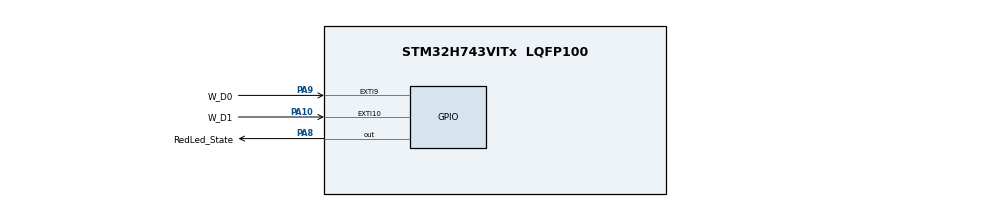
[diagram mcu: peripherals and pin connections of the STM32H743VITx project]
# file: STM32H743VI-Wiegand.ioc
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Mcu.Family=STM32H7
Mcu.Name=STM32H743VITx
Mcu.Package=LQFP100
NVIC.EXTI15_10_IRQn=true\:0\:0\:false\:false\:true\:true\:true
NVIC.EXTI9_5_IRQn=true\:0\:0\:false\:false\:true\:true\:true
NVIC.PriorityGroup=NVIC_PRIORITYGROUP_4
PA10.GPIO_Label=W_D1
PA10.GPIO_ModeDefaultEXTI=GPIO_MODE_IT_FALLING
PA10.GPIO_PuPd=GPIO_PULLUP
PA10.Signal=GPXTI10
PA8.GPIO_Label=RedLed_State
PA8.Signal=GPIO_Output
PA9.GPIO_Label=W_D0
PA9.GPIO_ModeDefaultEXTI=GPIO_MODE_IT_FALLING
PA9.GPIO_PuPd=GPIO_PULLUP
PA9.Signal=GPXTI9
ProjectManager.HeapSize=0x200
ProjectManager.StackSize=0x400
ProjectManager.TargetToolchain=STM32CubeIDE
RCC.ADCFreq_Value=129000000
RCC.APB1Freq_Value=64000000
RCC.APB2Freq_Value=64000000
RCC.APB3Freq_Value=64000000
RCC.APB4Freq_Value=64000000
RCC.CortexFreq_Value=64000000
RCC.HCLKFreq_Value=64000000
RCC.SYSCLKFreq_VALUE=64000000
RCC.USBFreq_Value=129000000
board=custom

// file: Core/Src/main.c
/* USER CODE BEGIN Header */
/**
 ******************************************************************************
 * @file           : main.c
 * @brief          : Main program body
 ******************************************************************************
 * @attention
 *
 * <h2><center>&copy; Copyright (c) 2021 STMicroelectronics.
 * All rights reserved.</center></h2>
 *
 * This software component is licensed by ST under BSD 3-Clause license,
 * the "License"; You may not use this file except in compliance with the
 * License. You may obtain a copy of the License at:
 *                        opensource.org/licenses/BSD-3-Clause
 *
 ******************************************************************************
 */
/* USER CODE END Header */
#include <ib_rfid.h>
#include "main.h"

void SystemClock_Config(void);
static void MX_GPIO_Init(void);

/* USER CODE BEGIN 0 */
void New_RFID(uint32_t code) {
	uint32_t card_rfid = code;
	HAL_GPIO_TogglePin(RedLed_State_GPIO_Port, RedLed_State_Pin);
}
/* USER CODE END 0 */

int main(void) {

	/* MCU Configuration--------------------------------------------------------*/

	/* Reset of all peripherals, Initializes the Flash interface and the Systick. */
	HAL_Init();

	/* Configure the system clock */
	SystemClock_Config();

	/* Initialize all configured peripherals */
	MX_GPIO_Init();
	/* USER CODE BEGIN 2 */
	HAL_GPIO_WritePin(RedLed_State_GPIO_Port, RedLed_State_Pin, GPIO_PIN_SET);
	rfid_init(W_D0_Pin, W_D1_Pin, 100, New_RFID);
	/* USER CODE END 2 */

	/* Infinite loop */
	/* USER CODE BEGIN WHILE */
	while (1) {
		rfid_loop();
		/* USER CODE END WHILE */

	}
}

void SystemClock_Config(void) {
	RCC_OscInitTypeDef RCC_OscInitStruct = { 0 };
	RCC_ClkInitTypeDef RCC_ClkInitStruct = { 0 };

	/** Supply configuration update enable
	 */
	HAL_PWREx_ConfigSupply(PWR_LDO_SUPPLY);
	/** Configure the main internal regulator output voltage
	 */
	__HAL_PWR_VOLTAGESCALING_CONFIG(PWR_REGULATOR_VOLTAGE_SCALE3);

	while (!__HAL_PWR_GET_FLAG(PWR_FLAG_VOSRDY)) {
	}
	/** Initializes the RCC Oscillators according to the specified parameters
	 * in the RCC_OscInitTypeDef structure.
	 */
	RCC_OscInitStruct.OscillatorType = RCC_OSCILLATORTYPE_HSI;
	RCC_OscInitStruct.HSIState = RCC_HSI_DIV1;
	RCC_OscInitStruct.HSICalibrationValue = RCC_HSICALIBRATION_DEFAULT;
	RCC_OscInitStruct.PLL.PLLState = RCC_PLL_NONE;
	if (HAL_RCC_OscConfig(&RCC_OscInitStruct) != HAL_OK) {
		Error_Handler();
	}
	/** Initializes the CPU, AHB and APB buses clocks
	 */
	RCC_ClkInitStruct.ClockType = RCC_CLOCKTYPE_HCLK | RCC_CLOCKTYPE_SYSCLK
			| RCC_CLOCKTYPE_PCLK1 | RCC_CLOCKTYPE_PCLK2 | RCC_CLOCKTYPE_D3PCLK1
			| RCC_CLOCKTYPE_D1PCLK1;
	RCC_ClkInitStruct.SYSCLKSource = RCC_SYSCLKSOURCE_HSI;
	RCC_ClkInitStruct.SYSCLKDivider = RCC_SYSCLK_DIV1;
	RCC_ClkInitStruct.AHBCLKDivider = RCC_HCLK_DIV1;
	RCC_ClkInitStruct.APB3CLKDivider = RCC_APB3_DIV1;
	RCC_ClkInitStruct.APB1CLKDivider = RCC_APB1_DIV1;
	RCC_ClkInitStruct.APB2CLKDivider = RCC_APB2_DIV1;
	RCC_ClkInitStruct.APB4CLKDivider = RCC_APB4_DIV1;

	if (HAL_RCC_ClockConfig(&RCC_ClkInitStruct, FLASH_LATENCY_1) != HAL_OK) {
		Error_Handler();
	}
}

static void MX_GPIO_Init(void) {
	GPIO_InitTypeDef GPIO_InitStruct = { 0 };

	/* GPIO Ports Clock Enable */
	__HAL_RCC_GPIOA_CLK_ENABLE();

	/*Configure GPIO pin Output Level */
	HAL_GPIO_WritePin(RedLed_State_GPIO_Port, RedLed_State_Pin, GPIO_PIN_RESET);

	/*Configure GPIO pin : RedLed_State_Pin */
	GPIO_InitStruct.Pin = RedLed_State_Pin;
	GPIO_InitStruct.Mode = GPIO_MODE_OUTPUT_PP;
	GPIO_InitStruct.Pull = GPIO_NOPULL;
	GPIO_InitStruct.Speed = GPIO_SPEED_FREQ_LOW;
	HAL_GPIO_Init(RedLed_State_GPIO_Port, &GPIO_InitStruct);

	/*Configure GPIO pins : W_D0_Pin W_D1_Pin */
	GPIO_InitStruct.Pin = W_D0_Pin | W_D1_Pin;
	GPIO_InitStruct.Mode = GPIO_MODE_IT_FALLING;
	GPIO_InitStruct.Pull = GPIO_PULLUP;
	HAL_GPIO_Init(GPIOA, &GPIO_InitStruct);

	/* EXTI interrupt init*/
	HAL_NVIC_SetPriority(EXTI9_5_IRQn, 0, 0);
	HAL_NVIC_EnableIRQ(EXTI9_5_IRQn);

	HAL_NVIC_SetPriority(EXTI15_10_IRQn, 0, 0);
	HAL_NVIC_EnableIRQ(EXTI15_10_IRQn);

}

/* USER CODE BEGIN 4 */
void HAL_GPIO_EXTI_Callback(uint16_t GPIO_Pin) {
	rfid_EXTI_pinDx(GPIO_Pin);
}
/* USER CODE END 4 */

void Error_Handler(void) {
	__disable_irq();
	while (1) {
	}
}

/************************ (C) COPYRIGHT STMicroelectronics *****END OF FILE****/
